# STM32WBA25xx register map
File version: 1.0
Registers are 32-bit, read-write, reset 0x0 unless marked. A register's access mark holds for its fields unless they carry their own. Offsets are from the block's base; [hi:lo] are bit positions; {n}, {i} and the like mark numbered series.

## GPIOA — General Purpose I/O
Base 0x42020000
Same registers: GPIOB 0x42020400, GPIOC 0x42020800, GPIOH 0x42021C00
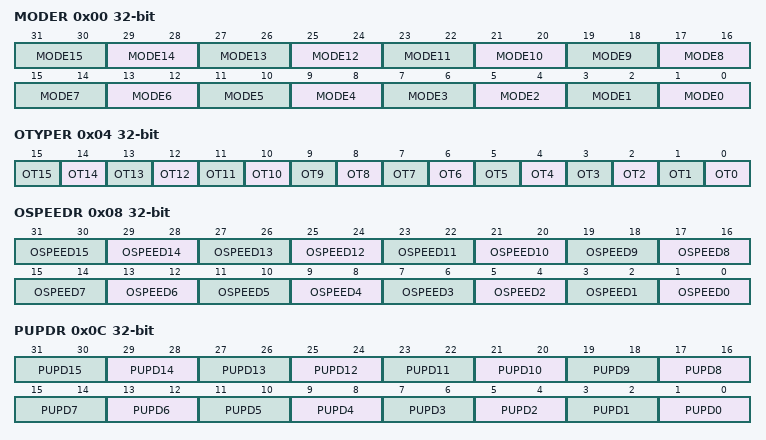
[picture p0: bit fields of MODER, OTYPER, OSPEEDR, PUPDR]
0x00 MODER — GPIO port mode register
  [2n+1:2n] MODE{n} (n=0..15)
0x04 OTYPER — GPIO port output type register
  [n] OT{n} (n=0..15)
0x08 OSPEEDR — GPIO port output speed register
  [2n+1:2n] OSPEED{n} (n=0..15)
0x0C PUPDR — GPIO port pull-up/pull-down register
  [2n+1:2n] PUPD{n} (n=0..15)
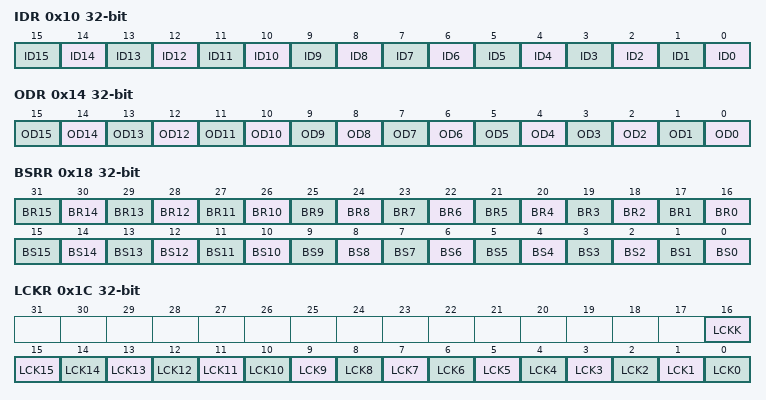
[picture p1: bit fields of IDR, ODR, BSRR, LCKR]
0x10 IDR — GPIO port input data register
  [n] ID{n} (n=0..15)
0x14 ODR — GPIO port output data register
  [n] OD{n} (n=0..15)
0x18 BSRR — GPIO port bit set/reset register
  [n+16] BR{n} (n=0..15), [n] BS{n} (n=0..15)
0x1C LCKR — GPIO port configuration lock register
  [16] LCKK, [n] LCK{n} (n=0..15)
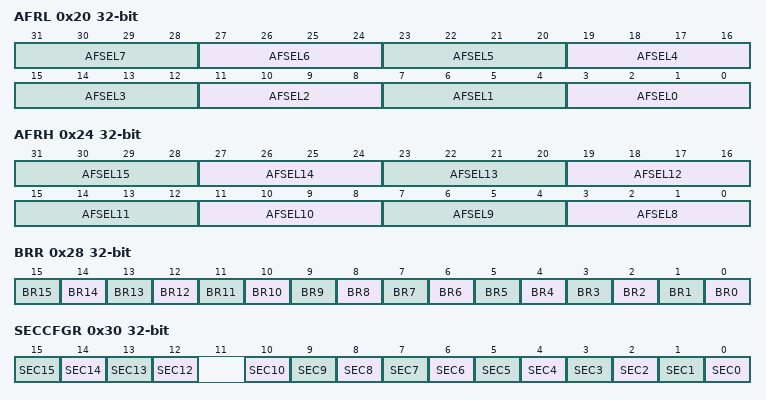
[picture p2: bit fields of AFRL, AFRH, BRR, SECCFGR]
0x20 AFRL — GPIO alternate function registers
  [4n+3:4n] AFSEL{n} (n=0..7)
0x24 AFRH — GPIO alternate function registers
  [4n-29:4n-32] AFSEL{n} (n=8..15)
0x28 BRR — GPIO Bit Reset register
  [n] BR{n} (n=0..15)
0x30 SECCFGR — GPIO secure configuration register
  [n] SEC{n} (n=12..15), [n] SEC{n} (n=0..10)

## AES — AES hardware accelerator
Base 0x420C0000
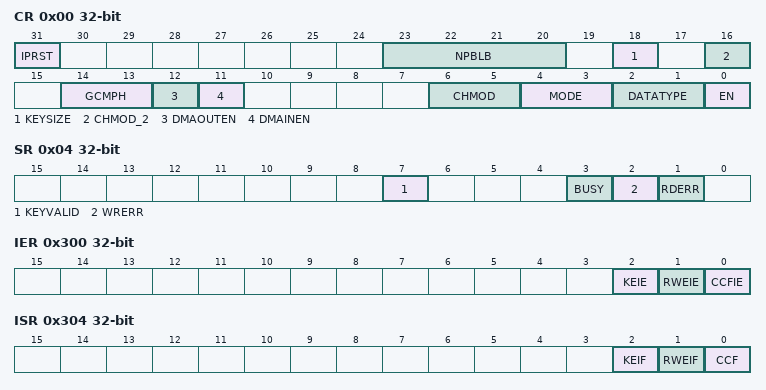
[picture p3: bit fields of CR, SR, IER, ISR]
0x00 CR — AES control register
  [31] IPRST — AES IP software reset
  [23:20] NPBLB — Number of padding bytes in payload last block
  [18] KEYSIZE — Key size selection
  [16] CHMOD_2 — AES Chaining Mode
  [14:13] GCMPH — GCM Phase
  [12] DMAOUTEN — Enable data output phase DMA management
  [11] DMAINEN — Enable data input phase DMA management
  [6:5] CHMOD — AES Chaining Mode
  [4:3] MODE — AES Mode Of Operation
  [2:1] DATATYPE — Data type selection
  [0] EN — AES Enable
0x04 SR — AES status register
  [7] KEYVALID — Key Valid Flag
  [3] BUSY — Busy Flag
  [2] WRERR — Write Error Flag
  [1] RDERR — Read Error Flag
0x08 DINR — AES data input register
  [31:0] DINR — AES Data Input Register
0x0C DOUTR — AES data output register
  [31:0] DOUTR — AES Data Output Register
{0x10+4i} KEYR{i} (i=0..3) — AES key register {i}
  [31:0] KEYR{i} — AES Key Register {i}
{0x20+4i} IVR{i} (i=0..3) — AES initialization vector register {i}
  [31:0] IVR{i} — AES Initialization Vector Register {i}
{0x20+4i} KEYR{i} (i=4..7) — AES key register {i}
  [31:0] KEYR{i} — AES Key Register {i}
{0x40+4i} SUSP{i}R (i=0..7) — AES Suspend register {i}
  [31:0] SUSP{i}R — AES Suspend registers {i}
0x300 IER — AES Interrupt Enable Register
  [2] KEIE — Key error interrupt enable
  [1] RWEIE — Read or write error Interrupt Enable
  [0] CCFIE — Computation complete flag interrupt enable
0x304 ISR — AES Interrupt Status Register
  [2] KEIF — Key error interrupt flag
  [1] RWEIF — Read or write error Interrupt flag
  [0] CCF — Computation complete flag
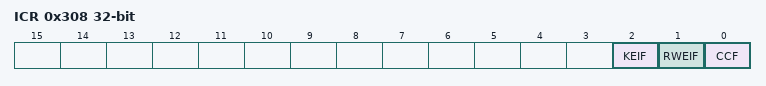
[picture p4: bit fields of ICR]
0x308 ICR — AES Interrupt Clear Register
  [2] KEIF — Key error interrupt flag clear
  [1] RWEIF — Read or write error Interrupt flag clear
  [0] CCF — Computation complete flag clear

## HASH
Base 0x420C0400
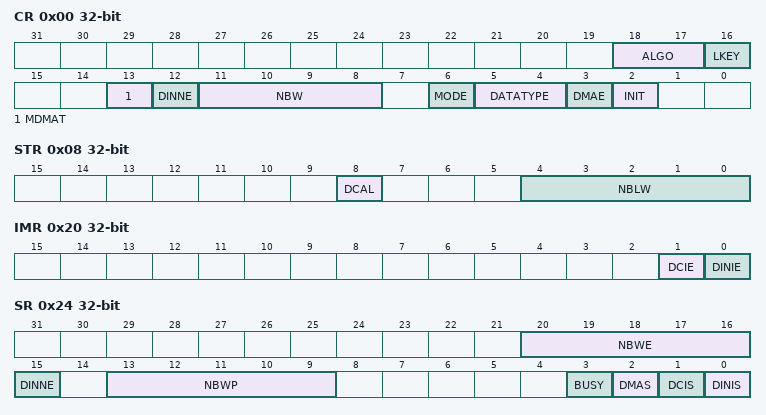
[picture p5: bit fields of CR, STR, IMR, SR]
0x00 CR — HASH control register
  [18:17] ALGO, [16] LKEY, [13] MDMAT, [12] DINNE, [11:8] NBW, [6] MODE, [5:4] DATATYPE, [3] DMAE, [2] INIT
0x04 DIN — HASH data input register
  [31:0] DATAIN — DATAIN[31:0] bits (Data input)
0x08 STR — HASH start register
  [8] DCAL, [4:0] NBLW
{0xC+4i} HR{i} (i=0..4) — HASH digest registers
0x20 IMR — HASH interrupt enable register
  [1] DCIE, [0] DINIE
0x24 SR — HASH status register
  [20:16] NBWE — NBWE[4:0] bits (Number of words expected)
  [15] DINNE — DINNE (DIN not empty)
  [13:9] NBWP — NBWP[4:0] bits (Number of words already pushed)
  [3] BUSY
  [2] DMAS
  [1] DCIS
  [0] DINIS
{0xF8+4i} CSR{i} (i=0..53) — HASH context swap registers
{0x310+4i} DIGEST_HR{i} (i=0..7) — HASH digest registers

## RNG
Base 0x420C0800
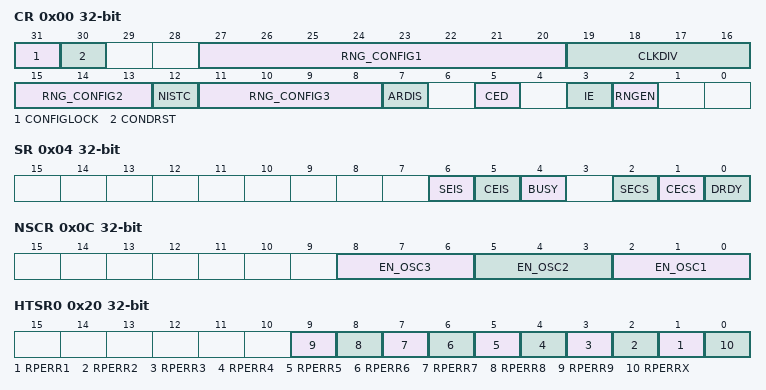
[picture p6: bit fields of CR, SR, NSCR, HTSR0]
0x00 CR — RNG control register
  [31] CONFIGLOCK — RNG configuration lock
  [30] CONDRST — Conditioning soft reset
  [27:20] RNG_CONFIG1 — RNG configuration 1
  [19:16] CLKDIV — Clock divider factor
    0=BY_1 (No clock division); 1=BY_2 (2 RNG clock cycles per internal RNG clock); 2=BY_4 (4 RNG clock cycles per internal RNG clock); 3=BY_8 (8 RNG clock cycles per internal RNG clock); 4=BY_16 (16 RNG clock cycles per internal RNG clock); 5=BY_32 (32 RNG clock cycles per internal RNG clock); 6=BY_64 (64 RNG clock cycles per internal RNG clock); 7=BY_128 (128 RNG clock cycles per internal RNG clock); 8=BY_256 (256 RNG clock cycles per internal RNG clock); 9=BY_512 (512 RNG clock cycles per internal RNG clock); 10=BY_1024 (1024 RNG clock cycles per internal RNG clock); 11=BY_2048 (2048 RNG clock cycles per internal RNG clock); 12=BY_4096 (4096 RNG clock cycles per internal RNG clock); 13=BY_8192 (8192 RNG clock cycles per internal RNG clock); 14=BY_16384 (16384 RNG clock cycles per internal RNG clock); 15=BY_32768 (32768 RNG clock cycles per internal RNG clock)
  [15:13] RNG_CONFIG2 — RNG configuration 2
  [12] NISTC — NIST custom
  [11:8] RNG_CONFIG3 — RNG configuration 3
  [7] ARDIS — Auto reset disable
  [5] CED — Clock error detection
  [3] IE — Interrupt enable
  [2] RNGEN — True random number generator enable
0x04 SR — RNG status register
  [6] SEIS, [5] CEIS, [4] BUSY, [2] SECS, [1] CECS, [0] DRDY
0x08 DR — RNG data register
  [31:0] RNDATA
0x0C NSCR — RNG noise source control register
  [8:6] EN_OSC3 — EN_OSC3[2:0] bits (Each bit drives one oscillator enable signal input of instance number 3, gated with RNGEN bit in RNG_CR (set bit to enable the oscillator). Bit is ignored otherwise.)
  [5:3] EN_OSC2 — EN_OSC2[2:0] bits (Each bit drives one oscillator enable signal input of instance number 2, gated with RNGEN bit in RNG_CR (set bit to enable the oscillator). Bit is ignored otherwise.)
  [2:0] EN_OSC1 — EN_OSC1[2:0] bits (Each bit drives one oscillator enable signal input of instance number 1, gated with RNGEN bit in RNG_CR (set bit to enable the oscillator). Bit is ignored otherwise.)
{0x10+4i} HTCR{i} (i=0..3) — RNG health test control register
  [31:0] HTCFG — health test configuration
0x20 HTSR0 — RNG health test status register
  [n] RPERR{n} (n=1..9) — Repetitive error for oscillator i
  [0] RPERRX — Repetitive error after the XOR
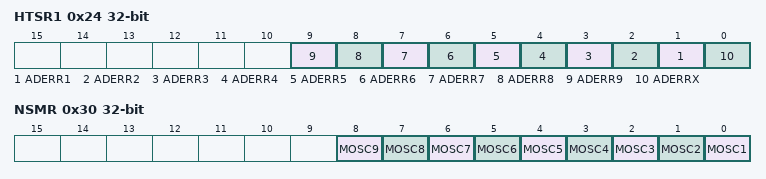
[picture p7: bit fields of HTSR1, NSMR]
0x24 HTSR1 — RNG health test status register
  [n] ADERR{n} (n=1..9) — Adaptative error for oscillator i
  [0] ADERRX — Adaptative error after the XOR
0x30 NSMR — RNG noise source mask register
  [n-1] MOSC{n} (n=1..9) — Mask oscillator i
